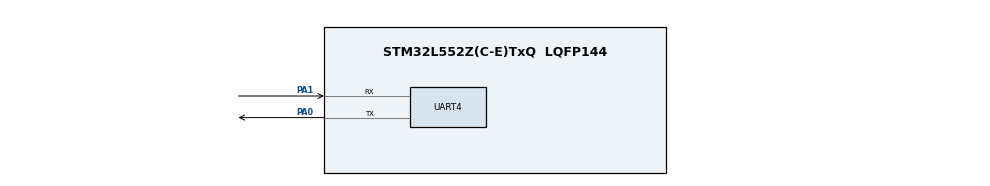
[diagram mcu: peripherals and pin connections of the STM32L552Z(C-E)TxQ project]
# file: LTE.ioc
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Mcu.Family=STM32L5
Mcu.Name=STM32L552Z(C-E)TxQ
Mcu.Package=LQFP144
NVIC.PriorityGroup=NVIC_PRIORITYGROUP_3
PA0.Mode=Asynchronous
PA0.Signal=UART4_TX
PA1.Mode=Asynchronous
PA1.Signal=UART4_RX
ProjectManager.HeapSize=0x200
ProjectManager.StackSize=0x400
ProjectManager.TargetToolchain=STM32CubeIDE
RCC.HSE_VALUE=16000000
RCC.HSI48_VALUE=48000000
RCC.HSI_VALUE=16000000
RCC.LSE_VALUE=32768
RCC.MSI_VALUE=4000000
RCC.VCOOutputFreq_Value=32000000
UART4.Parity=PARITY_NONE
VP_ICACHE_VS_ICACHE.Mode=DirectMappedCache
VP_PWR_VS_DBSignals.Mode=DisableDeadBatterySignals
VP_PWR_VS_SECSignals.Mode=Security/Privilege
board=custom

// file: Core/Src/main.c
/* USER CODE BEGIN Header */
/**
  ******************************************************************************
  * @file           : main.c
  * @brief          : Main program body
  ******************************************************************************
  * @attention
  *
  * Copyright (c) 2025 STMicroelectronics.
  * All rights reserved.
  *
  * This software is licensed under terms that can be found in the LICENSE file
  * in the root directory of this software component.
  * If no LICENSE file comes with this software, it is provided AS-IS.
  *
  ******************************************************************************
  */
/* USER CODE END Header */
#include "main.h"

UART_HandleTypeDef huart4;

void SystemClock_Config(void);
static void MX_GPIO_Init(void);
static void MX_UART4_Init(void);
static void MX_ICACHE_Init(void);

int main(void)
{

  /* MCU Configuration--------------------------------------------------------*/

  /* Reset of all peripherals, Initializes the Flash interface and the Systick. */
  HAL_Init();

  /* Configure the system clock */
  SystemClock_Config();

  /* Initialize all configured peripherals */
  MX_GPIO_Init();
  MX_UART4_Init();
  MX_ICACHE_Init();

  /* Infinite loop */
  /* USER CODE BEGIN WHILE */
  char tx_buf[] = "ATI\r\n";
  char rx_buf[100];
  while (1)
  {
    /* USER CODE END WHILE */

    /* USER CODE BEGIN 3 */
	  HAL_UART_Transmit(&huart4, (uint8_t *)tx_buf, sizeof(tx_buf) - 1, 1000);
	  HAL_UART_Receive(&huart4, (uint8_t *)rx_buf, sizeof(rx_buf), 2000);

	  HAL_Delay(3000);
  }
  /* USER CODE END 3 */
}

void SystemClock_Config(void)
{
  RCC_OscInitTypeDef RCC_OscInitStruct = {0};
  RCC_ClkInitTypeDef RCC_ClkInitStruct = {0};

  /** Configure the main internal regulator output voltage
  */
  if (HAL_PWREx_ControlVoltageScaling(PWR_REGULATOR_VOLTAGE_SCALE2) != HAL_OK)
  {
    Error_Handler();
  }

  /** Initializes the RCC Oscillators according to the specified parameters
  * in the RCC_OscInitTypeDef structure.
  */
  RCC_OscInitStruct.OscillatorType = RCC_OSCILLATORTYPE_MSI;
  RCC_OscInitStruct.MSIState = RCC_MSI_ON;
  RCC_OscInitStruct.MSICalibrationValue = RCC_MSICALIBRATION_DEFAULT;
  RCC_OscInitStruct.MSIClockRange = RCC_MSIRANGE_6;
  RCC_OscInitStruct.PLL.PLLState = RCC_PLL_NONE;
  if (HAL_RCC_OscConfig(&RCC_OscInitStruct) != HAL_OK)
  {
    Error_Handler();
  }

  /** Initializes the CPU, AHB and APB buses clocks
  */
  RCC_ClkInitStruct.ClockType = RCC_CLOCKTYPE_HCLK|RCC_CLOCKTYPE_SYSCLK
                              |RCC_CLOCKTYPE_PCLK1|RCC_CLOCKTYPE_PCLK2;
  RCC_ClkInitStruct.SYSCLKSource = RCC_SYSCLKSOURCE_MSI;
  RCC_ClkInitStruct.AHBCLKDivider = RCC_SYSCLK_DIV1;
  RCC_ClkInitStruct.APB1CLKDivider = RCC_HCLK_DIV1;
  RCC_ClkInitStruct.APB2CLKDivider = RCC_HCLK_DIV1;

  if (HAL_RCC_ClockConfig(&RCC_ClkInitStruct, FLASH_LATENCY_0) != HAL_OK)
  {
    Error_Handler();
  }
}

static void MX_ICACHE_Init(void)
{

  /** Enable instruction cache in 1-way (direct mapped cache)
  */
  if (HAL_ICACHE_ConfigAssociativityMode(ICACHE_1WAY) != HAL_OK)
  {
    Error_Handler();
  }
  if (HAL_ICACHE_Enable() != HAL_OK)
  {
    Error_Handler();
  }

}

static void MX_UART4_Init(void)
{

  huart4.Instance = UART4;
  huart4.Init.BaudRate = 115200;
  huart4.Init.WordLength = UART_WORDLENGTH_8B;
  huart4.Init.StopBits = UART_STOPBITS_1;
  huart4.Init.Parity = UART_PARITY_NONE;
  huart4.Init.Mode = UART_MODE_TX_RX;
  huart4.Init.HwFlowCtl = UART_HWCONTROL_NONE;
  huart4.Init.OverSampling = UART_OVERSAMPLING_16;
  huart4.Init.OneBitSampling = UART_ONE_BIT_SAMPLE_DISABLE;
  huart4.Init.ClockPrescaler = UART_PRESCALER_DIV1;
  huart4.AdvancedInit.AdvFeatureInit = UART_ADVFEATURE_NO_INIT;
  if (HAL_UART_Init(&huart4) != HAL_OK)
  {
    Error_Handler();
  }
  if (HAL_UARTEx_SetTxFifoThreshold(&huart4, UART_TXFIFO_THRESHOLD_1_8) != HAL_OK)
  {
    Error_Handler();
  }
  if (HAL_UARTEx_SetRxFifoThreshold(&huart4, UART_RXFIFO_THRESHOLD_1_8) != HAL_OK)
  {
    Error_Handler();
  }
  if (HAL_UARTEx_DisableFifoMode(&huart4) != HAL_OK)
  {
    Error_Handler();
  }

}

static void MX_GPIO_Init(void)
{

  /* GPIO Ports Clock Enable */
  __HAL_RCC_GPIOA_CLK_ENABLE();

}

void Error_Handler(void)
{
  __disable_irq();
  while (1)
  {
  }
}
